# STM32H533 register map
File version: 1.3
CPU: CM33 r0p0, little endian, MPU, FPU, 4 interrupt priority bits
Registers are 32-bit, read-write, reset 0x0 unless marked. A register's access mark holds for its fields unless they carry their own. Offsets are from the block's base; [hi:lo] are bit positions; {n}, {i} and the like mark numbered series; 'fields as' and 'values as' point back to an identical list.

## GTZC1_TZSC — GTZC1_MPCBBz register block
Base 0x40036400
Same registers: GTZC1_TZSC_S 0x50036400
0x00 GTZC1_TZSC_CR — GTZC1 TZSC control register
  [0] LCK — lock the configuration of GTZC1_TZSC_SECCFGRx and GTZC1_TZSC_PRIVCFGRx until next reset
    0=configuration of all GTZC1_TZSC_SECCFGRx and GTZC1_TZSC_PRIVCFGRx not locked; 1=configuration of all GTZC1_TZSC_SECCFGRx and GTZC1_TZSC_PRIVCFGRx locked
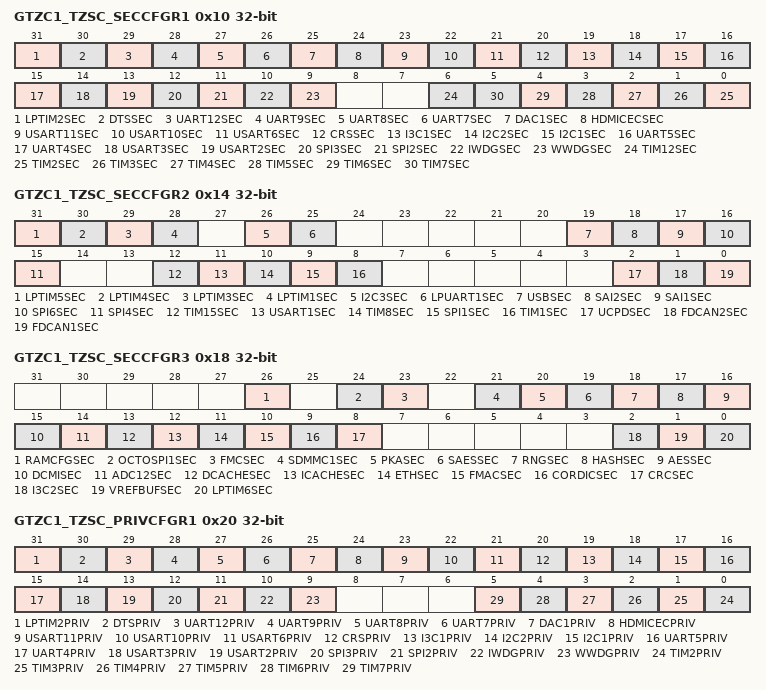
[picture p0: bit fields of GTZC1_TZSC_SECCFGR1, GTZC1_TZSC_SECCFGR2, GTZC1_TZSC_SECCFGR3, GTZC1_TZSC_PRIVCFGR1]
0x10 GTZC1_TZSC_SECCFGR1 — GTZC1 TZSC secure configuration register 1
  [all] fields
    0=non-secure; 1=secure
  [31] LPTIM2SEC — secure access mode for LPTIM2
  [30] DTSSEC — secure access mode for DTS
  [29] UART12SEC — secure access mode for UART12
  [28] UART9SEC — secure access mode for UART9
  [27] UART8SEC — secure access mode for UART8
  [26] UART7SEC — secure access mode for UART7
  [25] DAC1SEC — secure access mode for DAC1
  [24] HDMICECSEC — secure access mode for HDMICEC
  [23] USART11SEC — secure access mode for USART11
  [22] USART10SEC — secure access mode for USART10
  [21] USART6SEC — secure access mode for USART6
  [20] CRSSEC — secure access mode for CRS
  [19] I3C1SEC — secure access mode for I3C1
  [18] I2C2SEC — secure access mode for I2C2
  [17] I2C1SEC — secure access mode for I2C1
  [16] UART5SEC — secure access mode for UART5
  [15] UART4SEC — secure access mode for UART4
  [14] USART3SEC — secure access mode for USART3
  [13] USART2SEC — secure access mode for USART2
  [12] SPI3SEC — secure access mode for SPI3
  [11] SPI2SEC — secure access mode for SPI2
  [10] IWDGSEC — secure access mode for IWDG
  [9] WWDGSEC — secure access mode for WWDG
  [6] TIM12SEC — secure access mode for TIM12
  [n-2] TIM{n}SEC (n=2..7) — secure access mode for TIM{n}
0x14 GTZC1_TZSC_SECCFGR2 — GTZC1 TZSC secure configuration register 2
  [all] fields
    0=non-secure; 1=secure
  [31] LPTIM5SEC — secure access mode for LPTIM5
  [30] LPTIM4SEC — secure access mode for LPTIM4
  [29] LPTIM3SEC — secure access mode for LPTIM3
  [28] LPTIM1SEC — secure access mode for LPTIM1
  [26] I2C3SEC — secure access mode for I2C3
  [25] LPUART1SEC — secure access mode for LPUART
  [19] USBSEC — secure access mode for USB
  [18] SAI2SEC — secure access mode for SAI2
  [17] SAI1SEC — secure access mode for SAI1
  [16] SPI6SEC — secure access mode for SPI6
  [15] SPI4SEC — secure access mode for SPI4
  [12] TIM15SEC — secure access mode for TIM15
  [11] USART1SEC — secure access mode for USART1
  [10] TIM8SEC — secure access mode for TIM8
  [9] SPI1SEC — secure access mode for SPI1
  [8] TIM1SEC — secure access mode for TIM1
  [2] UCPDSEC — secure access mode for UCPD
  [1] FDCAN2SEC — secure access mode for FDCAN2
  [0] FDCAN1SEC — secure access mode for FDCAN1
0x18 GTZC1_TZSC_SECCFGR3 — GTZC1 TZSC secure configuration register 3
  [all] fields
    0=non-secure; 1=secure
  [26] RAMCFGSEC — secure access mode for RAMSCFG
  [24] OCTOSPI1SEC — secure access mode for OCTOSPI1
  [23] FMCSEC — secure access mode for FMC
  [21] SDMMC1SEC — secure access mode for SDMMC1
  [20] PKASEC — secure access mode for PKA
  [19] SAESSEC — secure access mode for SAES
  [18] RNGSEC — secure access mode for RNG
  [17] HASHSEC — secure access mode for HASH
  [16] AESSEC — secure access mode for AES
  [15] DCMISEC — secure access mode for DCMI
  [14] ADC12SEC — secure access mode for ADC1 and ADC2
  [13] DCACHESEC — secure access mode for DCACHE
  [12] ICACHESEC — secure access mode for ICACHE
  [11] ETHSEC — secure access mode for register of ETH
  [10] FMACSEC — secure access mode for FMAC
  [9] CORDICSEC — secure access mode for CORDIC
  [8] CRCSEC — secure access mode for CRC
  [2] I3C2SEC — secure access mode for I3C2
  [1] VREFBUFSEC — secure access mode for VREFBUF
  [0] LPTIM6SEC — secure access mode for LPTIM6
0x20 GTZC1_TZSC_PRIVCFGR1 — GTZC1 TZSC privilege configuration register 1
  [all] fields
    0=unprivileged; 1=privileged
  [31] LPTIM2PRIV — privileged access mode for LPTIM2
  [30] DTSPRIV — privileged access mode for DTS
  [29] UART12PRIV — privileged access mode for UART12
  [28] UART9PRIV — privileged access mode for UART9
  [27] UART8PRIV — privileged access mode for UART8
  [26] UART7PRIV — privileged access mode for UART7
  [25] DAC1PRIV — privileged access mode for DAC1
  [24] HDMICECPRIV — privileged access mode for HDMICEC
  [23] USART11PRIV — privileged access mode for USART11
  [22] USART10PRIV — privileged access mode for USART10
  [21] USART6PRIV — privileged access mode for USART6
  [20] CRSPRIV — privileged access mode for CRS
  [19] I3C1PRIV — privileged access mode for I3C1
  [18] I2C2PRIV — privileged access mode for I2C2
  [17] I2C1PRIV — privileged access mode for I2C1
  [16] UART5PRIV — privileged access mode for UART5
  [15] UART4PRIV — privileged access mode for UART4
  [14] USART3PRIV — privileged access mode for USART3
  [13] USART2PRIV — privileged access mode for USART2
  [12] SPI3PRIV — privileged access mode for SPI3
  [11] SPI2PRIV — privileged access mode for SPI2
  [10] IWDGPRIV — privileged access mode for IWDG
  [9] WWDGPRIV — privileged access mode for WWDG
  [n-2] TIM{n}PRIV (n=2..7) — privileged access mode for TIM{n}
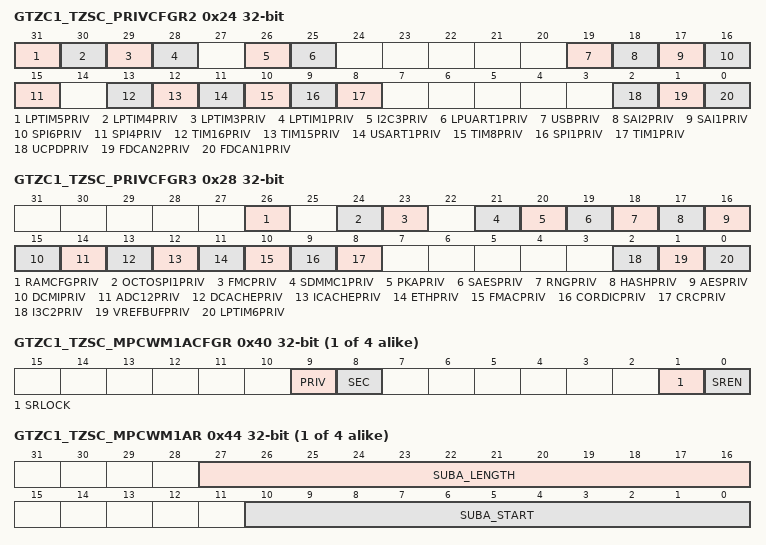
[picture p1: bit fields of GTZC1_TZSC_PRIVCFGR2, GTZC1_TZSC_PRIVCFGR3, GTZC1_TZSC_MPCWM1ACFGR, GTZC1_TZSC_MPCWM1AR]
0x24 GTZC1_TZSC_PRIVCFGR2 — GTZC1 TZSC privilege configuration register 2
  [all] fields
    0=unprivileged; 1=privileged
  [31] LPTIM5PRIV — privileged access mode for LPTIM5
  [30] LPTIM4PRIV — privileged access mode for LPTIM4
  [29] LPTIM3PRIV — privileged access mode for LPTIM3
  [28] LPTIM1PRIV — privileged access mode for LPTIM1
  [26] I2C3PRIV — privileged access mode for I2C3
  [25] LPUART1PRIV — privileged access mode for LPUART
  [19] USBPRIV — privileged access mode for USB
  [18] SAI2PRIV — privileged access mode for SAI2
  [17] SAI1PRIV — privileged access mode for SAI1
  [16] SPI6PRIV — privileged access mode for SPI6
  [15] SPI4PRIV — privileged access mode for SPI4
  [13] TIM16PRIV — privileged access mode for TIM16
  [12] TIM15PRIV — privileged access mode for TIM15
  [11] USART1PRIV — privileged access mode for USART1
  [10] TIM8PRIV — privileged access mode for TIM8
  [9] SPI1PRIV — privileged access mode for SPI1
  [8] TIM1PRIV — privileged access mode for TIM1
  [2] UCPDPRIV — privileged access mode for UCPD
  [1] FDCAN2PRIV — privileged access mode for FDCAN2
  [0] FDCAN1PRIV — privileged access mode for FDCAN1
0x28 GTZC1_TZSC_PRIVCFGR3 — GTZC1 TZSC privilege configuration register 3
  [all] fields
    0=unprivileged; 1=privileged
  [26] RAMCFGPRIV — privileged access mode for RAMSCFG
  [24] OCTOSPI1PRIV — privileged access mode for OCTOSPI1
  [23] FMCPRIV — privileged access mode for FMC
  [21] SDMMC1PRIV — privileged access mode for SDMMC1
  [20] PKAPRIV — privileged access mode for PKA
  [19] SAESPRIV — privileged access mode for SAES
  [18] RNGPRIV — privileged access mode for RNG
  [17] HASHPRIV — privileged access mode for HASH
  [16] AESPRIV — privileged access mode for AES
  [15] DCMIPRIV — privileged access mode for DCMI
  [14] ADC12PRIV — privileged access mode for ADC1 and ADC2
  [13] DCACHEPRIV — privileged access mode for DCACHE
  [12] ICACHEPRIV — privileged access mode for ICACHE
  [11] ETHPRIV — privileged access mode for register of ETH
  [10] FMACPRIV — privileged access mode for FMAC
  [9] CORDICPRIV — privileged access mode for CORDIC
  [8] CRCPRIV — privileged access mode for CRC
  [2] I3C2PRIV — privileged access mode for I3C2
  [1] VREFBUFPRIV — privileged access mode for VREFBUF
  [0] LPTIM6PRIV — privileged access mode for LPTIM6
{0x30+0x10*i} GTZC1_TZSC_MPCWM{i}ACFGR (i=1..4) — GTZC1 TZSC memory {i} subregion A watermark configuration register
  [9] PRIV — Privileged subregion A of base region x
    0=Privileged and unprivileged accesses are granted in subregion A; 1=Only privileged accesses are granted in subregion A of region x
  [8] SEC — Secure subregion A of base region x
    0=Only non-secure data accesses are granted to subregion A of region x; 1=Only secure data accesses are granted to subregion A of region x
  [1] SRLOCK — subregion A lock
    0=GTZC1_TZSC_MPCWMxCFGR, GTZC1_TZSC_MPCWMxAR and GTZC1_TZSC_MPCWMxBR can be written; 1=Writes to GTZC1_TZSC_MPCWMxCFGR, GTZC1_TZSC_MPCWMxAR and GTZC1_TZSC_MPCWMxBR are ignored
  [0] SREN — subregion A enable
    0=subregion A is disabled; 1=subregion A of region x is enabled
{0x34+0x10*i} GTZC1_TZSC_MPCWM{i}AR (i=1..4) — GTZC1 TZSC memory {i} subregion A watermark register
  [27:16] SUBA_LENGTH — Length of subregion A in region x
  [10:0] SUBA_START — Start of subregion A in region x
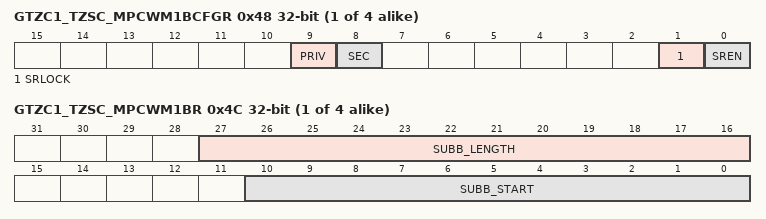
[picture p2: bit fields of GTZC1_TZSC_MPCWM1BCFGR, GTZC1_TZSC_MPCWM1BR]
{0x38+0x10*i} GTZC1_TZSC_MPCWM{i}BCFGR (i=1..4) — GTZC1 TZSC memory {i} subregion B watermark configuration register
  [9] PRIV — Privileged subregion B of base region x
    0=Privileged and unprivileged accesses are granted in subregion B; 1=Only privileged accesses are granted in subregion B of region x
  [8] SEC — Secure subregion B of base region x
    0=Only non-secure data accesses are granted to subregion B of region x; 1=Only secure data accesses are granted to subregion B of region x
  [1] SRLOCK — subregion B lock
    values as GTZC1_TZSC_MPCWM1ACFGR.SRLOCK
  [0] SREN — subregion B enable
    0=subregion B is disabled; 1=subregion B of region B is enabled
{0x3C+0x10*i} GTZC1_TZSC_MPCWM{i}BR (i=1..4) — GTZC1 TZSC memory {i} subregion B watermark register
  [27:16] SUBB_LENGTH — Length of subregion B in region x
  [10:0] SUBB_START — Start of subregion B in region x
